# f28p65x_cpu2_dma_cla_src_sel_regs register map
Vendor: Texas Instruments
Peripheral module from a debugger description file (folder C2000).
Address unit: 16 bits
Registers are 32-bit, read-write, no defined reset value unless marked. A register's access mark holds for its fields unless they carry their own. Offsets are as the file gives them; lines under a group give offsets from that group; [hi:lo] are bit positions; {n}, {i} and the like mark numbered series; 'fields as' and 'values as' point back to an identical list; <NAME> marks a mode.

## CPU2_DMA_CLA_SRC_SEL_REGS — CPU2 DMA CLA SRC SEL Registers
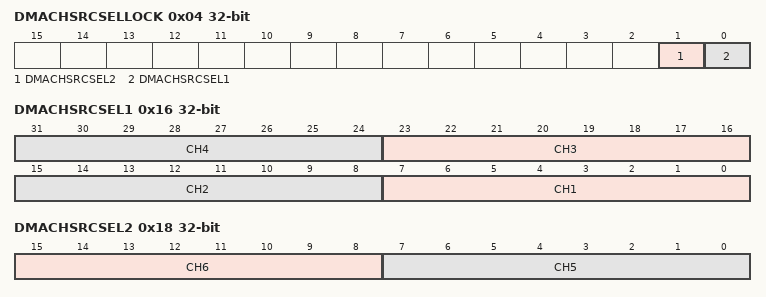
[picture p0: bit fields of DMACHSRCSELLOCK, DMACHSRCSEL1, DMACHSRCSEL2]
0x04 DMACHSRCSELLOCK — DMA Channel Triger Source Select Lock Register
  [1] DMACHSRCSEL2 — DMACHSRCSEL2 Register Lock bit
  [0] DMACHSRCSEL1 — DMACHSRCSEL1 Register Lock bit
0x16 DMACHSRCSEL1 — DMA Channel Trigger Source Select Register-1
  [8n-1:8n-8] CH{n} (n=1..4) — Selects the Trigger and Sync Source CH{n} of DMA
0x18 DMACHSRCSEL2 — DMA Channel Trigger Source Select Register-2
  [15:8] CH6 — Selects the Trigger and Sync Source CH6 of DMA
  [7:0] CH5 — Selects the Trigger and Sync Source CH5 of DMA
